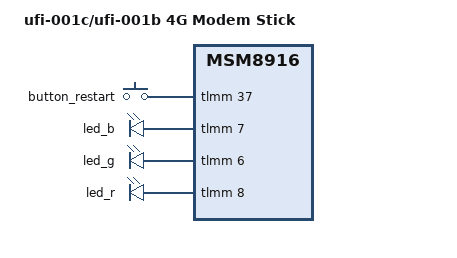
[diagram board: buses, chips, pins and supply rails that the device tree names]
// SPDX-License-Identifier: GPL-2.0-only

/dts-v1/;

#include "msm8916-ufi.dtsi"

/ {
	model = "ufi-001c/ufi-001b 4G Modem Stick";
	compatible = "thwc,ufi001c", "qcom,msm8916";
};

&button_restart {
	gpios = <&tlmm 37 GPIO_ACTIVE_HIGH>;
};

&led_b {
	gpios = <&tlmm 7 GPIO_ACTIVE_HIGH>;
};

&led_g {
	gpios = <&tlmm 6 GPIO_ACTIVE_HIGH>;
};

&led_r {
	gpios = <&tlmm 8 GPIO_ACTIVE_HIGH>;
};

&mpss {
	pinctrl-0 = <&sim_ctrl_default>;
	pinctrl-names = "default";
};

&button_default {
	pins = "gpio37";
	bias-pull-down;
};

&gpio_leds_default {
	pins = "gpio6", "gpio7", "gpio8";
};

/* This selects the external SIM card slot by default */
&tlmm {
	sim_ctrl_default: sim-ctrl-default-state {
		esim-sel-pins {
			pins = "gpio0", "gpio3";
			function = "gpio";
			bias-disable;
			output-low;
		};

		sim-en-pins {
			pins = "gpio1";
			function = "gpio";
			bias-disable;
			output-low;
		};

		sim-sel-pins {
			pins = "gpio2";
			function = "gpio";
			bias-disable;
			output-high;
		};
	};
};
